# EFR32MG21A010F1024IM32 register map
Vendor: Silicon Labs; Series: EFR32; File version: B
Registers are 32-bit, read-write, reset 0x0 unless marked. A register's access mark holds for its fields unless they carry their own. Offsets are from the block's base; [hi:lo] are bit positions; {n}, {i} and the like mark numbered series.

## ULFRCO_S — ULFRCO_S Registers
Base 0x40028000
Same registers: ULFRCO_NS 0x50028000
0x00 IPVERSION ro
  [31:0] IPVERSION — ULFRCO IP version
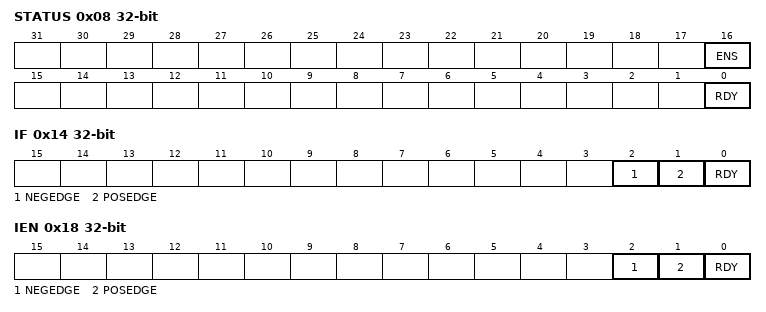
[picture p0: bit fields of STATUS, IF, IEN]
0x08 STATUS ro
  [16] ENS — Enable Status
  [0] RDY — Ready Status
0x14 IF
  [2] NEGEDGE — Negative Edge Interrupt Flag
  [1] POSEDGE — Positive Edge Interrupt Flag
  [0] RDY — Ready Interrupt Flag
0x18 IEN
  [2] NEGEDGE — Enable Negative Edge Interrupt
  [1] POSEDGE — Enable Positive Edge Interrupt
  [0] RDY — Enable Ready Interrupt

## MSC_S — MSC_S Registers
Base 0x40030000
Same registers: MSC_NS 0x50030000
0x00 IPVERSION ro
  [31:0] IPVERSION — IP Version ID
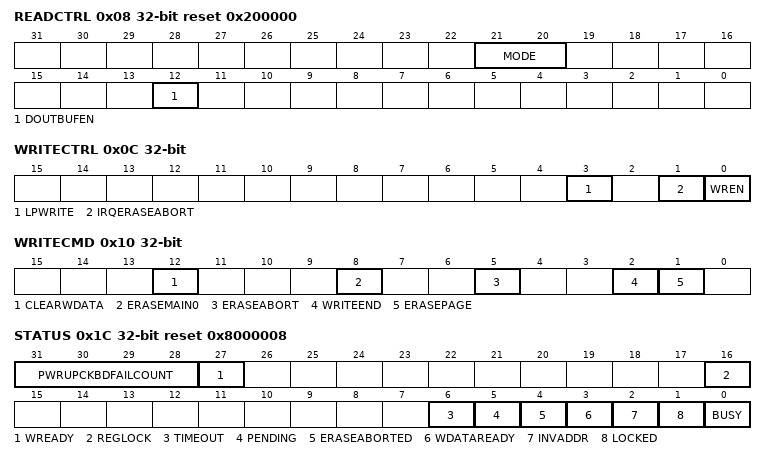
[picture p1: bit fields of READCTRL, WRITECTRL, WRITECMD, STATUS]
0x08 READCTRL reset 0x200000
  [21:20] MODE — Read Mode
    0=WS0 (Zero wait-states inserted in fetch or read transfers); 1=WS1 (One wait-state inserted for each fetch or read transfer.); 2=WS2 (Two wait-states inserted for eatch fetch or read transfer.); 3=WS3 (Three wait-states inserted for eatch fetch or read transfer.)
  [12] DOUTBUFEN — Flash dout pipeline buffer enable
0x0C WRITECTRL
  [3] LPWRITE — Low-Power Erase
  [1] IRQERASEABORT — Abort Page Erase on Interrupt
  [0] WREN — Enable Write/Erase Controller
0x10 WRITECMD wo
  [12] CLEARWDATA — Clear WDATA state
  [8] ERASEMAIN0 — Mass erase region 0
  [5] ERASEABORT — Abort erase sequence
  [2] WRITEEND — End Write Mode
  [1] ERASEPAGE
0x14 ADDRB
  [31:0] ADDRB — Page Erase or Write Address Buffer
0x18 WDATA
  [31:0] DATAW — Write Data
0x1C STATUS ro reset 0x8000008
  [31:28] PWRUPCKBDFAILCOUNT — Flash power up checkerboard pattern chec
  [27] WREADY — Flash Write Ready
  [16] REGLOCK — Register Lock Status
    0=UNLOCKED; 1=LOCKED
  [6] TIMEOUT — Write command timeout flag
  [5] PENDING — Write command is in queue
  [4] ERASEABORTED — The Current Flash Erase Operation Aborted
  [3] WDATAREADY — WDATA Write Ready
  [2] INVADDR — Invalid Write Address or Erase Page
  [1] LOCKED — Access Locked
  [0] BUSY — Erase/Write Busy
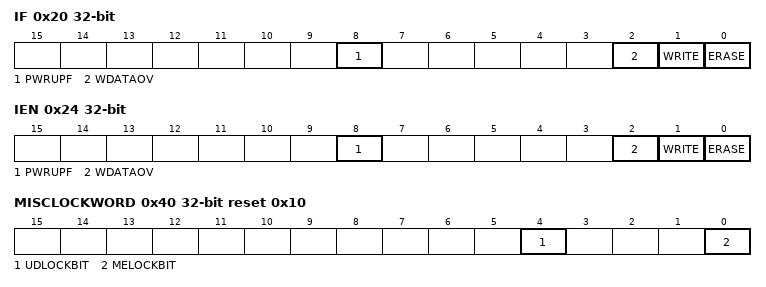
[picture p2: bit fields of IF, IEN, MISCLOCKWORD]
0x20 IF
  [8] PWRUPF — Flash Power Up Sequence Complete Flag
  [2] WDATAOV — Host write buffer overflow
  [1] WRITE — Host Write Done Interrupt Read Flag
  [0] ERASE — Host Erase Done Interrupt Read Flag
0x24 IEN
  [8] PWRUPF — Flash Power Up Sequence Complete
  [2] WDATAOV — write data buffer overflow irq enable
  [1] WRITE — Write Done Interrupt enable
  [0] ERASE — Erase Done Interrupt enable
0x34 USERDATASIZE ro reset 0x4
  [5:0] USERDATASIZE
0x38 CMD wo
  [0] PWRUP — Flash Power Up Command
0x3C LOCK wo
  [15:0] LOCKKEY — Configuration Lock
    0=LOCK; 0x1B71=UNLOCK
0x40 MISCLOCKWORD reset 0x10
  [4] UDLOCKBIT — User Data Lock
  [0] MELOCKBIT — Mass Erase Lock
{0x120+4i} PAGELOCK{i} (i=0..3)
  [31:0] LOCKBIT — page lock bit

## ICACHE0_S — ICACHE0_S Registers
Base 0x40034000
Same registers: ICACHE0_NS 0x50034000
0x00 IPVERSION ro — The read only IPVERSION field gives the version for this module. There may be minor software changes required for modules with different values of IPVERSION.
  [31:0] IPVERSION — IP version ID
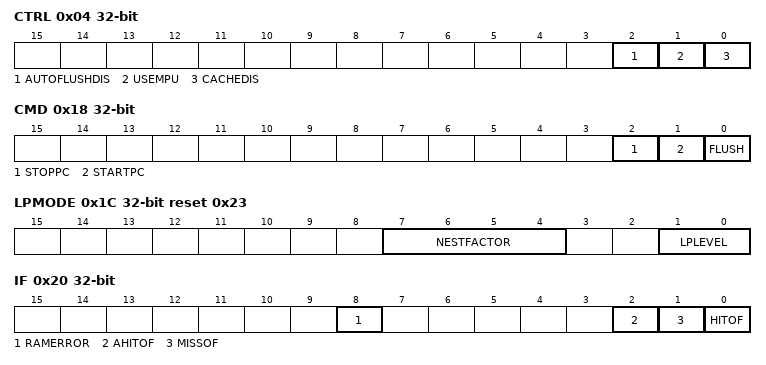
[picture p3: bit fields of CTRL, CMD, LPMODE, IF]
0x04 CTRL
  [2] AUTOFLUSHDIS — Automatic Flushing Disable
  [1] USEMPU
  [0] CACHEDIS — Cache Disable
0x08 PCHITS ro
  [31:0] PCHITS — Performance Counter Hits
0x0C PCMISSES ro
  [31:0] PCMISSES — Performance Counter Misses
0x10 PCAHITS ro
  [31:0] PCAHITS — Performance Counter Advanced Hits
0x14 STATUS ro
  [0] PCRUNNING
0x18 CMD wo
  [2] STOPPC — Stop Performance Counters
  [1] STARTPC — Start Performance Counters
  [0] FLUSH
0x1C LPMODE reset 0x23
  [7:4] NESTFACTOR — Low Power Nest Factor
  [1:0] LPLEVEL — Low Power Level
    0=BASIC (Base instruction cache functionality); 1=ADVANCED (Advanced buffering mode, where the cache uses the fetch pattern to predict highly accessed data and store it in low-energy memory); 3=MINACTIVITY (Minimum activity mode, which allows the cache to minimize activity in logic that it predicts has a low probability being used. This mode can introduce wait-states into the instruction fetch stream when the cache exits one of its low-activity states. The number of wait-states introduced is small, but users running with 0-wait-state memory and wishing to reduce the variability that the cache might introduce with additional wait-states may wish to lower the cache low-power level. Note, this mode includes the advanced buffering mode functionality.)
0x20 IF
  [8] RAMERROR — RAM error Interrupt Flag
  [2] AHITOF — Advanced Hit Overflow Interrupt Flag
  [1] MISSOF — Miss Overflow Interrupt Flag
  [0] HITOF — Hit Overflow Interrupt Flag
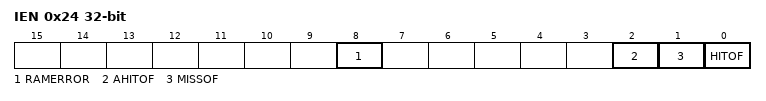
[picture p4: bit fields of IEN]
0x24 IEN
  [8] RAMERROR — RAM error Interrupt Enable
  [2] AHITOF — Advanced Hit Overflow Interrupt Enable
  [1] MISSOF — Miss Overflow Interrupt Enable
  [0] HITOF — Hit Overflow Interrupt Enable
